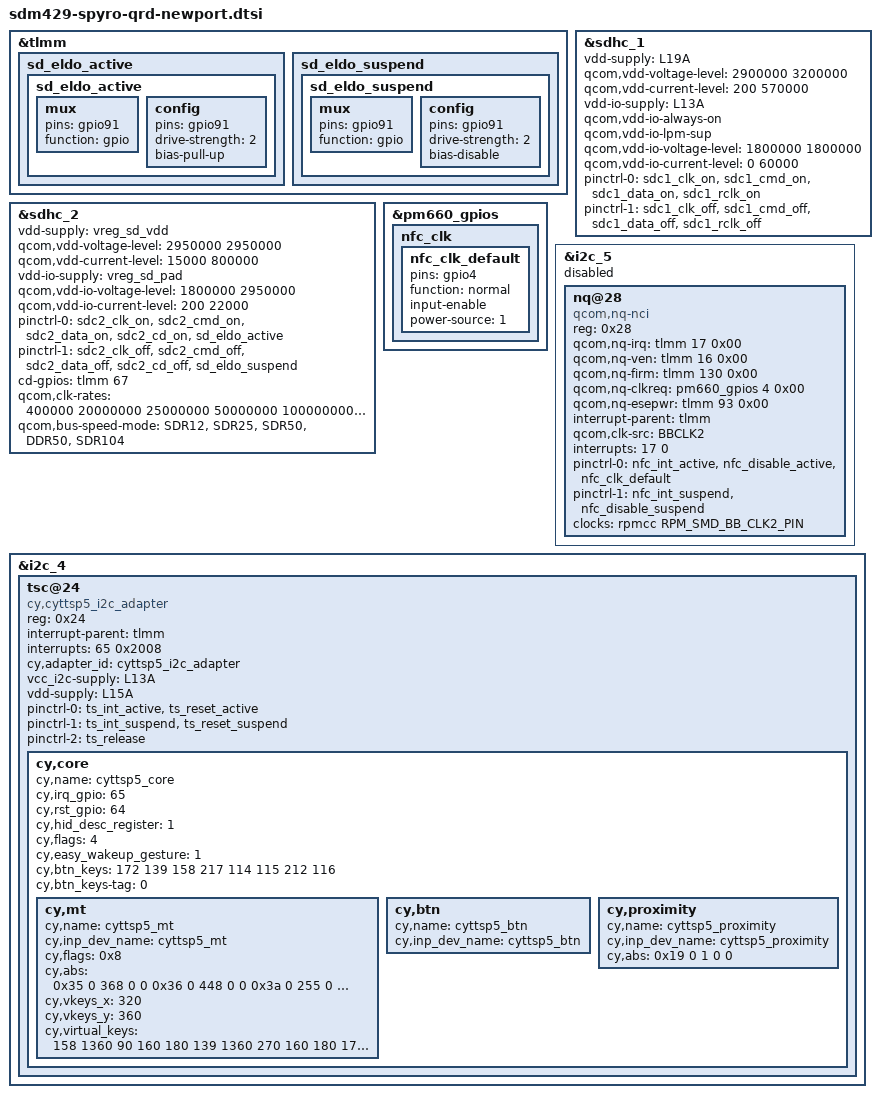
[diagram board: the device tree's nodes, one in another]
/*
 * Copyright (c) 2020, The Linux Foundation. All rights reserved.
 *
 * This program is free software; you can redistribute it and/or modify
 * it under the terms of the GNU General Public License version 2 and
 * only version 2 as published by the Free Software Foundation.
 *
 * This program is distributed in the hope that it will be useful,
 * but WITHOUT ANY WARRANTY; without even the implied warranty of
 * MERCHANTABILITY or FITNESS FOR A PARTICULAR PURPOSE.  See the
 * GNU General Public License for more details.
 */

#include "sdm429-board-common.dtsi"
#include "sdm429-spyro-qrd-evt-camera.dtsi"

&tlmm {
	sd_eldo_active {
		sd_eldo_active: sd_eldo_active {
			mux {
				pins = "gpio91";
				function = "gpio";
			};

			config {
				pins = "gpio91";
				drive-strength = <2>;
				bias-pull-up;
			};
		};
	};

	sd_eldo_suspend {
		sd_eldo_suspend: sd_eldo_suspend {
			mux {
				pins = "gpio91";
				function = "gpio";
			};

			config {
				pins = "gpio91";
				drive-strength = <2>;
				bias-disable;
			};
		};
	};
};

&sdhc_1 {
	/* device core power supply */
	vdd-supply = <&L19A>;
	qcom,vdd-voltage-level = <2900000 3200000>;
	qcom,vdd-current-level = <200 570000>;

	/* device communication power supply */
	vdd-io-supply = <&L13A>;
	qcom,vdd-io-always-on;
	qcom,vdd-io-lpm-sup;
	qcom,vdd-io-voltage-level = <1800000 1800000>;
	qcom,vdd-io-current-level = <0 60000>;

	pinctrl-names = "active", "sleep";
	pinctrl-0 = <&sdc1_clk_on &sdc1_cmd_on &sdc1_data_on &sdc1_rclk_on>;
	pinctrl-1 = <&sdc1_clk_off &sdc1_cmd_off &sdc1_data_off &sdc1_rclk_off>;

	status = "ok";
};

&sdhc_2 {
	/* device core power supply for sd card*/
	vdd-supply = <&vreg_sd_vdd>;
	qcom,vdd-voltage-level = <2950000 2950000>;
	qcom,vdd-current-level = <15000 800000>;

	/* device communication power supply for msm_io*/
	vdd-io-supply = <&vreg_sd_pad>;
	qcom,vdd-io-voltage-level = <1800000 2950000>;
	qcom,vdd-io-current-level = <200 22000>;

	pinctrl-names = "active", "sleep";
	pinctrl-0 = <&sdc2_clk_on &sdc2_cmd_on &sdc2_data_on &sdc2_cd_on
				&sd_eldo_active>;
	pinctrl-1 = <&sdc2_clk_off &sdc2_cmd_off &sdc2_data_off &sdc2_cd_off
				&sd_eldo_suspend>;

	cd-gpios = <&tlmm 67 0x0>;

	qcom,clk-rates = <400000 20000000 25000000 50000000 100000000
				200000000>;

	qcom,bus-speed-mode = "SDR12", "SDR25", "SDR50", "DDR50", "SDR104";

	status = "ok";
};

&pm660_gpios {
	nfc_clk {
		nfc_clk_default: nfc_clk_default {
			pins = "gpio4";
			function = "normal";
			input-enable;
			power-source = <1>;
		};
	};
};

&i2c_5 { /* BLSP2 QUP1 (NFC) */
	#address-cells = <1>;
	#size-cells = <0>;

	status = "disable";
	nq@28 {
		compatible = "qcom,nq-nci";
		reg = <0x28>;
		qcom,nq-irq = <&tlmm 17 0x00>;
		qcom,nq-ven = <&tlmm 16 0x00>;
		qcom,nq-firm = <&tlmm 130 0x00>;
		qcom,nq-clkreq = <&pm660_gpios 4 0x00>;
		qcom,nq-esepwr = <&tlmm 93 0x00>;
		interrupt-parent = <&tlmm>;
		qcom,clk-src = "BBCLK2";
		interrupts = <17 0>;
		interrupt-names = "nfc_irq";
		pinctrl-names = "nfc_active", "nfc_suspend";
		pinctrl-0 = <&nfc_int_active &nfc_disable_active
						&nfc_clk_default>;
		pinctrl-1 = <&nfc_int_suspend &nfc_disable_suspend>;
		clocks = <&rpmcc RPM_SMD_BB_CLK2_PIN>;
		clock-names = "ref_clk";
	};
};

&i2c_4 {
	status = "ok";

	tsc@24 {
		compatible = "cy,cyttsp5_i2c_adapter";
		reg = <0x24>;

		interrupt-parent = <&tlmm>;
		interrupts = <65 0x2008>;
		cy,adapter_id = "cyttsp5_i2c_adapter";
		vcc_i2c-supply = <&L13A>;
		vdd-supply = <&L15A>;
		pinctrl-names = "pmx_ts_active", "pmx_ts_suspend",
				"pmx_ts_release";
		pinctrl-0 = <&ts_int_active &ts_reset_active>;
		pinctrl-1 = <&ts_int_suspend &ts_reset_suspend>;
		pinctrl-2 = <&ts_release>;

		cy,core {
			cy,name = "cyttsp5_core";
			cy,irq_gpio = <65>;
			cy,rst_gpio = <64>;
			cy,hid_desc_register = <1>;
			cy,flags = <4>;
			cy,easy_wakeup_gesture = <1>;
			cy,btn_keys = <172 139 158 217 114 115 212 116>;
			cy,btn_keys-tag = <0>;

			cy,mt {
				cy,name = "cyttsp5_mt";

				cy,inp_dev_name = "cyttsp5_mt";
				cy,flags = <0x8>;
				cy,abs =
					<0x35 0 368 0 0
					 0x36 0 448 0 0
					 0x3a 0 255 0 0
					 0xffff 0 255 0 0
					 0x39 0 15 0 0
					 0x30 0 255 0 0
					 0x31 0 255 0 0
					 0x34 0xffffff81 127 0 0
					 0x37 0 1 0 0
					 0x3b 0 255 0 0>;

				cy,vkeys_x = <320>;
				cy,vkeys_y = <360>;

				cy,virtual_keys =
					<158 1360 90 160 180
					 139 1360 270 160 180
					 172 1360 450 160 180
					 217 1360 630 160 180>;
			};

			cy,btn {
				cy,name = "cyttsp5_btn";

				cy,inp_dev_name = "cyttsp5_btn";
			};

			cy,proximity {
				cy,name = "cyttsp5_proximity";

				cy,inp_dev_name = "cyttsp5_proximity";
				cy,abs = <0x19 0 1 0 0>;
			};
		};
	};

};
